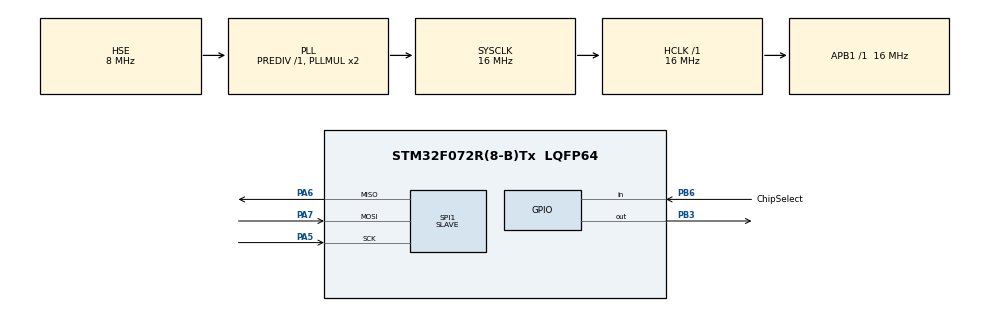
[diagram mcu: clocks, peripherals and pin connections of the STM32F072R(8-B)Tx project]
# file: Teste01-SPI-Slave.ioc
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Mcu.Family=STM32F0
Mcu.Name=STM32F072R(8-B)Tx
Mcu.Package=LQFP64
NVIC.SPI1_IRQn=true\:0\:0\:false\:false\:true\:true\:true\:true
PA5.Mode=Full_Duplex_Slave
PA5.Signal=SPI1_SCK
PA6.Mode=Full_Duplex_Slave
PA6.Signal=SPI1_MISO
PA7.Mode=Full_Duplex_Slave
PA7.Signal=SPI1_MOSI
PB3.Signal=GPIO_Output
PB6.GPIO_Label=ChipSelect
PB6.Signal=GPIO_Input
PF0-OSC_IN.Mode=HSE-External-Oscillator
PF0-OSC_IN.Signal=RCC_OSC_IN
PF1-OSC_OUT.Mode=HSE-External-Oscillator
PF1-OSC_OUT.Signal=RCC_OSC_OUT
ProjectManager.HeapSize=0x200
ProjectManager.StackSize=0x400
ProjectManager.TargetToolchain=STM32CubeIDE
RCC.AHBFreq_Value=16000000
RCC.APB1Freq_Value=16000000
RCC.APB1TimFreq_Value=16000000
RCC.HCLKFreq_Value=16000000
RCC.PLLSourceVirtual=RCC_PLLSOURCE_HSE
RCC.SYSCLKFreq_VALUE=16000000
RCC.SYSCLKSource=RCC_SYSCLKSOURCE_PLLCLK
SPI1.DataSize=SPI_DATASIZE_8BIT
SPI1.Direction=SPI_DIRECTION_2LINES
SPI1.Mode=SPI_MODE_SLAVE
SPI1.VirtualType=VM_SLAVE
board=custom

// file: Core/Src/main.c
/* USER CODE BEGIN Header */
/**
  ******************************************************************************
  * @file           : main.c
  * @brief          : Main program body
  ******************************************************************************
  * @attention
  *
  * Copyright (c) 2024 STMicroelectronics.
  * All rights reserved.
  *
  * This software is licensed under terms that can be found in the LICENSE file
  * in the root directory of this software component.
  * If no LICENSE file comes with this software, it is provided AS-IS.
  *
  ******************************************************************************
  */
/* USER CODE END Header */
#include "main.h"

SPI_HandleTypeDef hspi1;

/* USER CODE BEGIN PV */
uint8_t TxIdx = 0;
uint8_t RxCnt = 0;
uint8_t data_tx[10]={10,20,30,40,50,60,70,80,90,100};
uint8_t data_rx[10];
uint8_t spiRxBuffer[2];
uint8_t spiTxBuffer[2]={0xCC,0xCD};

/* USER CODE END PV */

void SystemClock_Config(void);
static void MX_GPIO_Init(void);
static void MX_SPI1_Init(void);

int main(void)
{

  /* MCU Configuration--------------------------------------------------------*/

  /* Reset of all peripherals, Initializes the Flash interface and the Systick. */
  HAL_Init();

  /* USER CODE BEGIN Init */
  HAL_StatusTypeDef status;

  /* USER CODE END Init */

  /* Configure the system clock */
  SystemClock_Config();

  /* Initialize all configured peripherals */
  MX_GPIO_Init();
  MX_SPI1_Init();

  /* Infinite loop */
  /* USER CODE BEGIN WHILE */
  while (1)
  {
      // O Slave espera o tempo que for necessário (HAL_MAX_DELAY)
      status = HAL_SPI_Receive(&hspi1, spiRxBuffer, 2, HAL_MAX_DELAY);

      if (status == HAL_OK) {
          // Se recebeu 0xAB, liga o LED do PA9
          if (spiRxBuffer[0] == 0xAB) {
              HAL_GPIO_WritePin(GPIOB, GPIO_PIN_3, GPIO_PIN_SET);
          } else {
              HAL_GPIO_WritePin(GPIOB GPIO_PIN_3, GPIO_PIN_RESET);
          }
      }
  }
  /* USER CODE END 3 */
}

void SystemClock_Config(void)
{
  RCC_OscInitTypeDef RCC_OscInitStruct = {0};
  RCC_ClkInitTypeDef RCC_ClkInitStruct = {0};

  /** Initializes the RCC Oscillators according to the specified parameters
  * in the RCC_OscInitTypeDef structure.
  */
  RCC_OscInitStruct.OscillatorType = RCC_OSCILLATORTYPE_HSE;
  RCC_OscInitStruct.HSEState = RCC_HSE_ON;
  RCC_OscInitStruct.PLL.PLLState = RCC_PLL_ON;
  RCC_OscInitStruct.PLL.PLLSource = RCC_PLLSOURCE_HSE;
  RCC_OscInitStruct.PLL.PLLMUL = RCC_PLL_MUL2;
  RCC_OscInitStruct.PLL.PREDIV = RCC_PREDIV_DIV1;
  if (HAL_RCC_OscConfig(&RCC_OscInitStruct) != HAL_OK)
  {
    Error_Handler();
  }

  /** Initializes the CPU, AHB and APB buses clocks
  */
  RCC_ClkInitStruct.ClockType = RCC_CLOCKTYPE_HCLK|RCC_CLOCKTYPE_SYSCLK
                              |RCC_CLOCKTYPE_PCLK1;
  RCC_ClkInitStruct.SYSCLKSource = RCC_SYSCLKSOURCE_PLLCLK;
  RCC_ClkInitStruct.AHBCLKDivider = RCC_SYSCLK_DIV1;
  RCC_ClkInitStruct.APB1CLKDivider = RCC_HCLK_DIV1;

  if (HAL_RCC_ClockConfig(&RCC_ClkInitStruct, FLASH_LATENCY_0) != HAL_OK)
  {
    Error_Handler();
  }
}

static void MX_SPI1_Init(void)
{

  /* SPI1 parameter configuration*/
  hspi1.Instance = SPI1;
  hspi1.Init.Mode = SPI_MODE_SLAVE;
  hspi1.Init.Direction = SPI_DIRECTION_2LINES;
  hspi1.Init.DataSize = SPI_DATASIZE_8BIT;
  hspi1.Init.CLKPolarity = SPI_POLARITY_LOW;
  hspi1.Init.CLKPhase = SPI_PHASE_1EDGE;
  hspi1.Init.NSS = SPI_NSS_SOFT;
  hspi1.Init.FirstBit = SPI_FIRSTBIT_MSB;
  hspi1.Init.TIMode = SPI_TIMODE_DISABLE;
  hspi1.Init.CRCCalculation = SPI_CRCCALCULATION_DISABLE;
  hspi1.Init.CRCPolynomial = 7;
  hspi1.Init.CRCLength = SPI_CRC_LENGTH_DATASIZE;
  hspi1.Init.NSSPMode = SPI_NSS_PULSE_DISABLE;
  if (HAL_SPI_Init(&hspi1) != HAL_OK)
  {
    Error_Handler();
  }

}

static void MX_GPIO_Init(void)
{
  GPIO_InitTypeDef GPIO_InitStruct = {0};

  /* GPIO Ports Clock Enable */
  __HAL_RCC_GPIOF_CLK_ENABLE();
  __HAL_RCC_GPIOA_CLK_ENABLE();
  __HAL_RCC_GPIOB_CLK_ENABLE();

  /*Configure GPIO pin Output Level */
  HAL_GPIO_WritePin(GPIOA, GPIO_PIN_9, GPIO_PIN_RESET);

  /*Configure GPIO pin : PA9 */
  GPIO_InitStruct.Pin = GPIO_PIN_9;
  GPIO_InitStruct.Mode = GPIO_MODE_OUTPUT_PP;
  GPIO_InitStruct.Pull = GPIO_NOPULL;
  GPIO_InitStruct.Speed = GPIO_SPEED_FREQ_LOW;
  HAL_GPIO_Init(GPIOA, &GPIO_InitStruct);

  /*Configure GPIO pin : ChipSelect_Pin */
  GPIO_InitStruct.Pin = ChipSelect_Pin;
  GPIO_InitStruct.Mode = GPIO_MODE_INPUT;
  GPIO_InitStruct.Pull = GPIO_NOPULL;
  HAL_GPIO_Init(ChipSelect_GPIO_Port, &GPIO_InitStruct);

}

void Error_Handler(void)
{
  __disable_irq();
  while (1)
  {
  }
}
